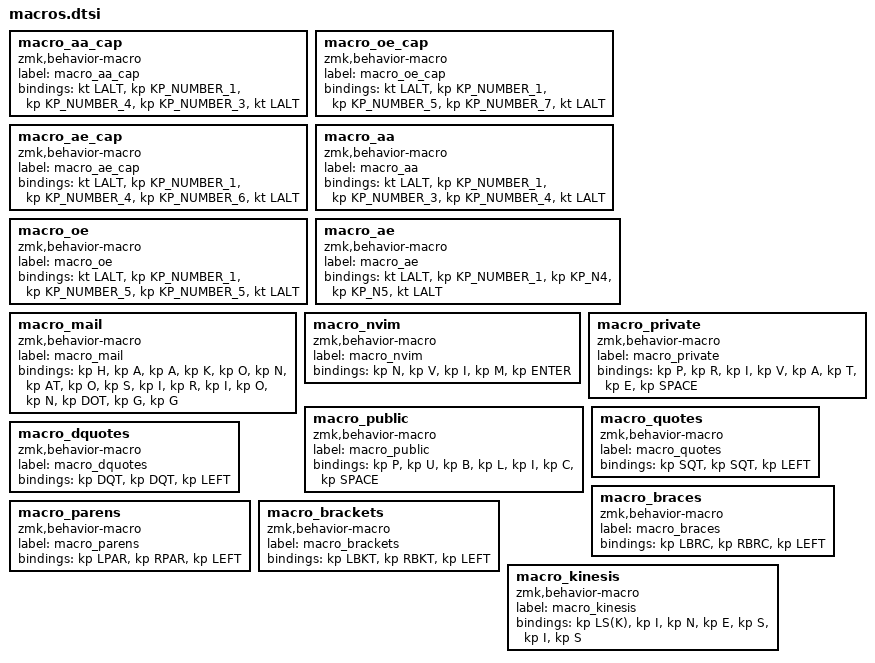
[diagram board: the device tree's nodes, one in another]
macro_aa_cap: macro_aa_cap{
compatible = "zmk,behavior-macro";
label = "macro_aa_cap";
#binding-cells = <0>;
bindings = <&kt LALT>, <&kp KP_NUMBER_1>, <&kp KP_NUMBER_4>, <&kp KP_NUMBER_3>, <&kt LALT>;
};
macro_oe_cap: macro_oe_cap{
compatible = "zmk,behavior-macro";
label = "macro_oe_cap";
#binding-cells = <0>;
bindings = <&kt LALT>, <&kp KP_NUMBER_1>, <&kp KP_NUMBER_5>, <&kp KP_NUMBER_7>, <&kt LALT>;
};
macro_ae_cap: macro_ae_cap{
compatible = "zmk,behavior-macro";
label = "macro_ae_cap";
#binding-cells = <0>;
bindings = <&kt LALT>, <&kp KP_NUMBER_1>, <&kp KP_NUMBER_4>, <&kp KP_NUMBER_6>, <&kt LALT>;
};
macro_aa: macro_aa{
compatible = "zmk,behavior-macro";
label = "macro_aa";
#binding-cells = <0>;
bindings = <&kt LALT>, <&kp KP_NUMBER_1>, <&kp KP_NUMBER_3>, <&kp KP_NUMBER_4>, <&kt LALT>;
};
macro_oe: macro_oe{
compatible = "zmk,behavior-macro";
label = "macro_oe";
#binding-cells = <0>;
bindings = <&kt LALT>, <&kp KP_NUMBER_1>, <&kp KP_NUMBER_5>, <&kp KP_NUMBER_5>, <&kt LALT>;
};
macro_ae: macro_ae{
compatible = "zmk,behavior-macro";
label = "macro_ae";
#binding-cells = <0>;
bindings = <&kt LALT>, <&kp KP_NUMBER_1>, <&kp KP_N4>, <&kp KP_N5>, <&kt LALT>;
};
macro_mail: macro_mail{
compatible = "zmk,behavior-macro";
label = "macro_mail";
#binding-cells = <0>;
bindings = <&kp H>, <&kp A>, <&kp A>, <&kp K>, <&kp O>, <&kp N>, <&kp AT>, <&kp O>, <&kp S>, <&kp I>, <&kp R>, <&kp I>, <&kp O>, <&kp N>, <&kp DOT>, <&kp G>, <&kp G>;
};
macro_nvim: macro_nvim{
compatible = "zmk,behavior-macro";
label = "macro_nvim";
#binding-cells = <0>;
bindings = <&kp N>, <&kp V>, <&kp I>, <&kp M>, <&kp ENTER>;
};
macro_private: macro_private{
compatible = "zmk,behavior-macro";
label = "macro_private";
#binding-cells = <0>;
bindings = <&kp P>, <&kp R>, <&kp I>, <&kp V>, <&kp A>, <&kp T>, <&kp E>, <&kp SPACE>;
};
macro_public: macro_public{
compatible = "zmk,behavior-macro";
label = "macro_public";
#binding-cells = <0>;
bindings = <&kp P>, <&kp U>, <&kp B>, <&kp L>, <&kp I>, <&kp C>, <&kp SPACE>;
};
macro_quotes: macro_quotes{
compatible = "zmk,behavior-macro";
label = "macro_quotes";
#binding-cells = <0>;
bindings = <&kp SQT>, <&kp SQT>, <&kp LEFT>;
};
macro_dquotes: macro_dquotes{
compatible = "zmk,behavior-macro";
label = "macro_dquotes";
#binding-cells = <0>;
bindings = <&kp DQT>, <&kp DQT>, <&kp LEFT>;
};
macro_braces: macro_braces{
compatible = "zmk,behavior-macro";
label = "macro_braces";
#binding-cells = <0>;
bindings = <&kp LBRC>, <&kp RBRC>, <&kp LEFT>;
};
macro_parens: macro_parens{
compatible = "zmk,behavior-macro";
label = "macro_parens";
#binding-cells = <0>;
bindings = <&kp LPAR>, <&kp RPAR>, <&kp LEFT>;
};
macro_brackets: macro_brackets{
compatible = "zmk,behavior-macro";
label = "macro_brackets";
#binding-cells = <0>;
bindings = <&kp LBKT>, <&kp RBKT>, <&kp LEFT>;
};
macro_kinesis: macro_kinesis{
compatible = "zmk,behavior-macro";
label = "macro_kinesis";
#binding-cells = <0>;
bindings = <&kp LS(K)>, <&kp I>, <&kp N>, <&kp E>, <&kp S>, <&kp I>, <&kp S>;
};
